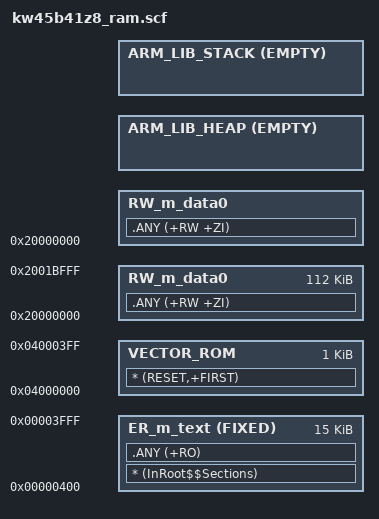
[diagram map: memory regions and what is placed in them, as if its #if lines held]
#! armcc -E
/*
** ###################################################################
**     Processors:          KW45B41Z82AFPA
**                          KW45B41Z82AFTA
**                          KW45B41Z83AFPA
**                          KW45B41Z83AFTA
**
**     Compiler:            Keil ARM C/C++ Compiler
**     Reference manual:    Rev. 5, Jan. 6, 2022
**     Version:             rev. 1.0, 2020-05-12
**     Build:               b220320
**
**     Abstract:
**         Linker file for the Keil ARM C/C++ Compiler
**
**     Copyright 2016 Freescale Semiconductor, Inc.
**     Copyright 2016-2022 NXP
**     All rights reserved.
**
**     SPDX-License-Identifier: BSD-3-Clause
**
**     http:                 www.nxp.com
**     mail:                 support@nxp.com
**
** ###################################################################
*/


/* Sizes */
#if (defined(__stack_size__))
  #define Stack_Size                   __stack_size__
#else
  #define Stack_Size                   0x0400
#endif

#if (defined(__heap_size__))
  #define Heap_Size                    __heap_size__
#else
  #define Heap_Size                    0x0400
#endif

#define  m_interrupts_start            0x04000000
#define  m_interrupts_size             0x00000400

#define  m_text_start                  0x00000400
#define  m_text_size                   0x00003C00

#define  m_data0_start                  0x20000000
#define  m_data0_size                   0x0001C000

LR_m_text m_text_start m_text_size {   ; load region size_region
  ER_m_text m_text_start FIXED m_text_size { ; load address = execution address
    * (InRoot$$Sections)
    .ANY (+RO)
  }

  RW_m_data0 m_data0_start m_data0_size { ; RW data
    .ANY (+RW +ZI)
  }
  RW_m_data0 m_data0_start m_data0_size-Stack_Size-Heap_Size { ; RW data
    .ANY (+RW +ZI)
  }
  ARM_LIB_HEAP +0 EMPTY Heap_Size {    ; Heap region growing up
  }
  ARM_LIB_STACK m_data0_start+m_data0_size EMPTY -Stack_Size { ; Stack region growing down
  }
}

LR_m_interrupts m_interrupts_start m_interrupts_size {
  VECTOR_ROM m_interrupts_start m_interrupts_size { ; load address = execution address
    * (RESET,+FIRST)
  }
}
